# 3067M register map
File version: 1.0
Registers are 32-bit, access per field, reset 0x0 unless marked. A register's access mark holds for its fields unless they carry their own. Offsets are from the block's base; [hi:lo] are bit positions; {n}, {i} and the like mark numbered series.

## APT0 (part 1 of 2) — APT0 peripheral interface
Base 0x14A00000
Same registers: APT{n} {0x14A00000+0x1000*n} (n=1..15)
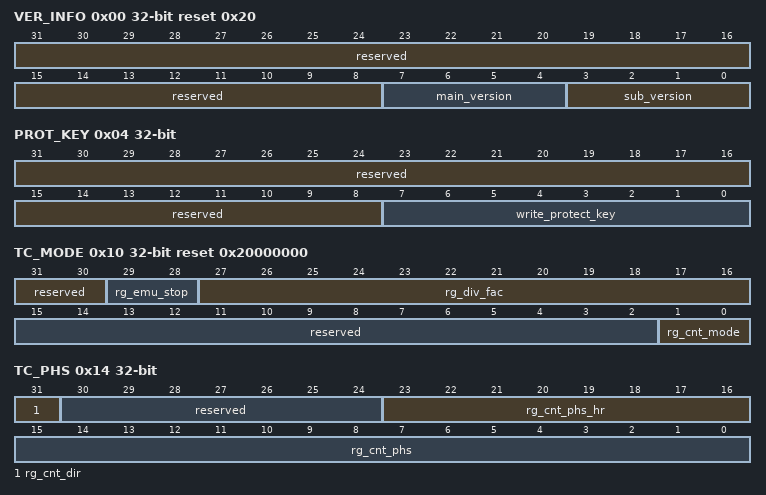
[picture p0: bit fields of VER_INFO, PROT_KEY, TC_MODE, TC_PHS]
0x00 VER_INFO ro reset 0x20 — VER_INFO为版本信息寄存器。
  [31:8] reserved — 保留。
  [7:4] main_version — 主版本号。
  [3:0] sub_version — 子版本号。
0x04 PROT_KEY — PROT_KEY为保护配置寄存器。
  [31:8] reserved ro — 保留。
  [7:0] write_protect_key rw — 写保护关键字。 0x55：软件可写支持写保护的寄存器； 其他：软件不可写支持写保护的寄存器，只可读。
0x10 TC_MODE reset 0x20000000 — TC_MODE为计数模式寄存器。
  [31:30] reserved ro — 保留。
  [29:28] rg_emu_stop rw — CPU debug模式，APT停止的方式。注意，如果停止APT，那么在CPU debug模式下，整个APT都会停止工作，包括输出控制功能。 0X：不停止； 10：停止分频计数器（DIVCNT）和时基计数器（TCCNT）； 11：停止APT。
  [27:16] rg_div_fac rw — 分频系数。 分频倍数 = 分频系数 +1。
  [15:2] reserved ro — 保留。
  [1:0] rg_cnt_mode rw — 时基计数器（TCCNT）的工作模式。 00：递增计数； 01：递减计数； 10：先增后减计数； 11：冻结。
0x14 TC_PHS — TC_PHS为计数相位控制寄存器。
  [31] rg_cnt_dir rw — 当APTCNTSYNC有效时，更新时基计数器（TCCNT）的计数方向，仅在先增后减计数模式有效。 0：递减； 1：递增。
  [30:24] reserved ro — 保留。
  [23:16] rg_cnt_phs_hr rw — 当APTCNTSYNC有效时，更新时基计数器（TCCNT）的计数值，高精度部分。
  [15:0] rg_cnt_phs rw — 当APTCNTSYNC有效时，更新时基计数器（TCCNT）的计数值。
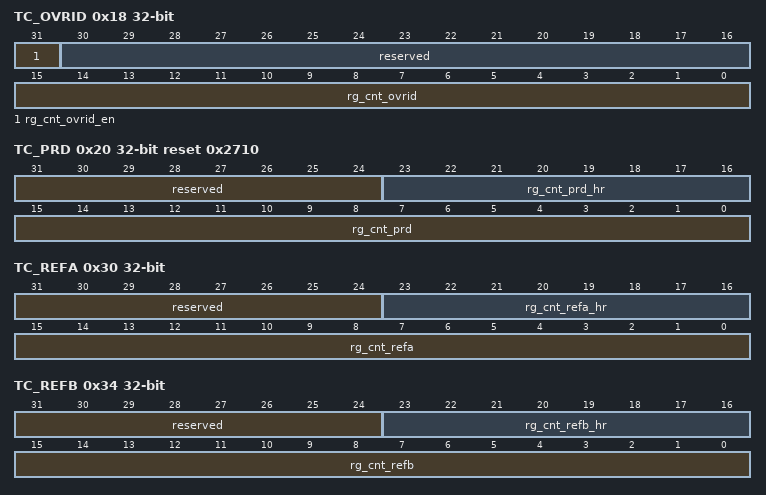
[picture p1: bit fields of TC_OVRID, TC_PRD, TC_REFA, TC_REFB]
0x18 TC_OVRID — TC_OVRID为计数器初始化寄存器。
  [31] rg_cnt_ovrid_en rw write-1-clears — 时基计数器（TCCNT）和分频计数器（DIVCNT）的初始化使能。 0：无效； 1：初始化时基计数器（TCCNT）为rg_cnt_ovrid，初始化分频计数器（DIVCNT）为0。
  [30:16] reserved ro — 保留。
  [15:0] rg_cnt_ovrid rw — 初始化时基计数器（TCCNT）的计数值。
0x20 TC_PRD reset 0x2710 — TC_PRD为计数周期寄存器。支持LINK。
  [31:24] reserved ro — 保留。
  [23:16] rg_cnt_prd_hr rw — 时基计数器（TCCNT）的计数周期，高精度部分。
  [15:0] rg_cnt_prd rw — 时基计数器（TCCNT）的计数周期。
0x30 TC_REFA — TC_REFA为计数参考值A寄存器。支持LINK。
  [31:24] reserved ro — 保留。
  [23:16] rg_cnt_refa_hr rw — 时基计数器（TCCNT）的参考值A，高精度部分。
  [15:0] rg_cnt_refa rw — 时基计数器（TCCNT）的参考值A。
0x34 TC_REFB — TC_REFB为计数参考值B寄存器。支持LINK。
  [31:24] reserved ro — 保留。
  [23:16] rg_cnt_refb_hr rw — 时基计数器（TCCNT）的参考值B，高精度部分。
  [15:0] rg_cnt_refb rw — 时基计数器（TCCNT）的参考值B。
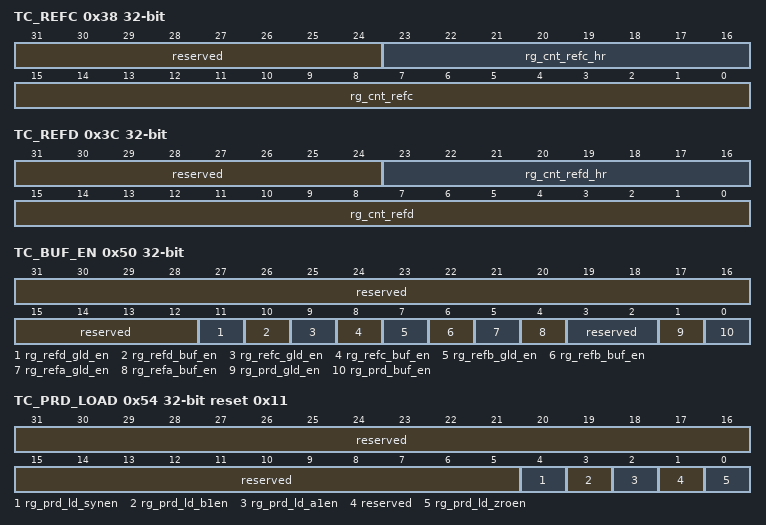
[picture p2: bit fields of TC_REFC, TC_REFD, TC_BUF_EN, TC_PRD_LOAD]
0x38 TC_REFC — TC_REFC为计数参考值C寄存器。支持LINK。
  [31:24] reserved ro — 保留。
  [23:16] rg_cnt_refc_hr rw — 时基计数器（TCCNT）的参考值C，高精度部分。
  [15:0] rg_cnt_refc rw — 时基计数器（TCCNT）的参考值C。
0x3C TC_REFD — TC_REFD为计数参考值D寄存器。支持LINK。
  [31:24] reserved ro — 保留。
  [23:16] rg_cnt_refd_hr rw — 时基计数器（TCCNT）的参考值D，高精度部分。
  [15:0] rg_cnt_refd rw — 时基计数器（TCCNT）的参考值D。
0x50 TC_BUF_EN — TC_BUF_EN为计数器缓存加载使能寄存器。
  [31:12] reserved ro — 保留。
  [11] rg_refd_gld_en rw — TC_REFD寄存器的缓存加载模式选择。 0：独立加载； 1：全局加载。
  [10] rg_refd_buf_en rw — TC_REFD寄存器的缓存使能。 0：不使能； 1：使能。
  [9] rg_refc_gld_en rw — TC_REFC寄存器的缓存加载模式选择。 0：独立加载； 1：全局加载。
  [8] rg_refc_buf_en rw — TC_REFC寄存器的缓存使能。 0：不使能； 1：使能。
  [7] rg_refb_gld_en rw — TC_REFB寄存器的缓存加载模式选择。 0：独立加载； 1：全局加载。
  [6] rg_refb_buf_en rw — TC_REFB寄存器的缓存使能。 0：不使能； 1：使能。
  [5] rg_refa_gld_en rw — TC_REFA寄存器的缓存加载模式选择。 0：独立加载； 1：全局加载。
  [4] rg_refa_buf_en rw — TC_REFA寄存器的缓存使能。 0：不使能； 1：使能。
  [3:2] reserved ro — 保留。
  [1] rg_prd_gld_en rw — TC_PRD寄存器的缓存加载模式选择。 0：独立加载； 1：全局加载。
  [0] rg_prd_buf_en rw — TC_PRD寄存器的缓存使能。 0：不使能； 1：使能。
0x54 TC_PRD_LOAD reset 0x11 — TC_PRD_LOAD为计数周期寄存器独立加载触发信号选择寄存器。
  [31:5] reserved ro — 保留。
  [4] rg_prd_ld_synen rw — 选择APTxSYNCI有效时，是否使能TC_PRD寄存器的独立加载。 0：不使能； 1：使能。
  [3] rg_prd_ld_b1en rw — 选择EMEVTB1有效时，是否使能TC_PRD寄存器的独立加载。 0：不使能； 1：使能。
  [2] rg_prd_ld_a1en rw — 选择EMEVTA1有效时，是否使能TC_PRD寄存器的独立加载。 0：不使能； 1：使能。
  [1] reserved ro — 保留。
  [0] rg_prd_ld_zroen rw — 选择CNT_ZERO有效时，是否使能TC_PRD寄存器的独立加载。 0：不使能； 1：使能。
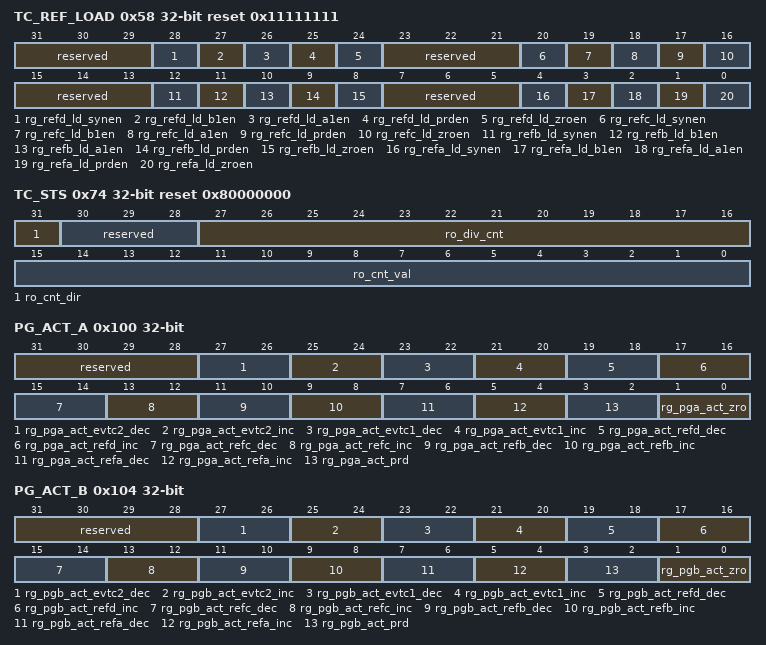
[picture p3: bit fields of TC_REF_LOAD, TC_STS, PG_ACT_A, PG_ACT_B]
0x58 TC_REF_LOAD reset 0x11111111 — TC_REF_LOAD为计数参考值寄存器独立加载触发信号选择寄存器。
  [31:29] reserved ro — 保留。
  [28] rg_refd_ld_synen rw — 选择APTxSYNCI有效时，是否使能TC_REFD寄存器的独立加载。 0：不使能； 1：使能。
  [27] rg_refd_ld_b1en rw — 选择EMEVTB1有效时，是否使能TC_REFD寄存器的独立加载。 0：不使能； 1：使能。
  [26] rg_refd_ld_a1en rw — 选择EMEVTA1有效时，是否使能TC_REFD寄存器的独立加载。 0：不使能； 1：使能。
  [25] rg_refd_ld_prden rw — 选择CNT_PRD有效时，是否使能TC_REFD寄存器的独立加载。 0：不使能； 1：使能。
  [24] rg_refd_ld_zroen rw — 选择CNT_ZERO有效时，是否使能TC_REFD寄存器的独立加载。 0：不使能； 1：使能。
  [23:21] reserved ro — 保留。
  [20] rg_refc_ld_synen rw — 选择APTxSYNCI有效时，是否使能TC_REFC寄存器的独立加载。 0：不使能； 1：使能。
  [19] rg_refc_ld_b1en rw — 选择EMEVTB1有效时，是否使能TC_REFC寄存器的独立加载。 0：不使能； 1：使能。
  [18] rg_refc_ld_a1en rw — 选择EMEVTA1有效时，是否使能TC_REFC寄存器的独立加载。 0：不使能； 1：使能。
  [17] rg_refc_ld_prden rw — 选择CNT_PRD有效时，是否使能TC_REFC寄存器的独立加载。 0：不使能； 1：使能。
  [16] rg_refc_ld_zroen rw — 选择CNT_ZERO有效时，是否使能TC_REFC寄存器的独立加载。 0：不使能； 1：使能。
  [15:13] reserved ro — 保留。
  [12] rg_refb_ld_synen rw — 选择APTxSYNCI有效时，是否使能TC_REFB寄存器的独立加载。 0：不使能； 1：使能。
  [11] rg_refb_ld_b1en rw — 选择EMEVTB1有效时，是否使能TC_REFB寄存器的独立加载。 0：不使能； 1：使能。
  [10] rg_refb_ld_a1en rw — 选择EMEVTA1有效时，是否使能TC_REFB寄存器的独立加载。 0：不使能； 1：使能。
  [9] rg_refb_ld_prden rw — 选择CNT_PRD有效时，是否使能TC_REFB寄存器的独立加载。 0：不使能； 1：使能。
  [8] rg_refb_ld_zroen rw — 选择CNT_ZERO有效时，是否使能TC_REFB寄存器的独立加载。 0：不使能； 1：使能。
  [7:5] reserved ro — 保留。
  [4] rg_refa_ld_synen rw — 选择APTxSYNCI有效时，是否使能TC_REFA寄存器的独立加载。 0：不使能； 1：使能。
  [3] rg_refa_ld_b1en rw — 选择EMEVTB1有效时，是否使能TC_REFA寄存器的独立加载。 0：不使能； 1：使能。
  [2] rg_refa_ld_a1en rw — 选择EMEVTA1有效时，是否使能TC_REFA寄存器的独立加载。 0：不使能； 1：使能。
  [1] rg_refa_ld_prden rw — 选择CNT_PRD有效时，是否使能TC_REFA寄存器的独立加载。 0：不使能； 1：使能。
  [0] rg_refa_ld_zroen rw — 选择CNT_ZERO有效时，是否使能TC_REFA寄存器的独立加载。 0：不使能； 1：使能。
0x74 TC_STS ro reset 0x80000000 — TC_STS为计数状态寄存器。
  [31] ro_cnt_dir — 时基计数器（TCCNT）的当前计数方向。 0：递减计数； 1：递增计数。
  [30:28] reserved — 保留。
  [27:16] ro_div_cnt — 分频计数器（DIVCNT）的当前计数值。
  [15:0] ro_cnt_val — 时基计数器（TCCNT）的当前计数值。
0x100 PG_ACT_A — PG_ACT_A为PG_PWMA动作配置寄存器。支持LINK。
  [31:28] reserved ro — 保留。
  [27:26] rg_pga_act_evtc2_dec rw — AEVTC2有效且TCCNT计数方向递减时，PG_PWMA的动作。 00：无影响； 01：置为低电平； 10：置为高电平； 11：翻转电平。
  [25:24] rg_pga_act_evtc2_inc rw — AEVTC2有效且TCCNT计数方向递增时，PG_PWMA的动作。 00：无影响； 01：置为低电平； 10：置为高电平； 11：翻转电平。
  [23:22] rg_pga_act_evtc1_dec rw — AEVTC1有效且TCCNT计数方向递减时，PG_PWMA的动作。 00：无影响； 01：置为低电平； 10：置为高电平； 11：翻转电平。
  [21:20] rg_pga_act_evtc1_inc rw — AEVTC1有效且TCCNT计数方向递增时，PG_PWMA的动作。 00：无影响； 01：置为低电平； 10：置为高电平； 11：翻转电平。
  [19:18] rg_pga_act_refd_dec rw — CNT_REFD有效且TCCNT计数方向递减时，PG_PWMA的动作。 00：无影响； 01：置为低电平； 10：置为高电平； 11：翻转电平。
  [17:16] rg_pga_act_refd_inc rw — CNT_REFD有效且TCCNT计数方向递增时，PG_PWMA的动作。 00：无影响； 01：置为低电平； 10：置为高电平； 11：翻转电平。
  [15:14] rg_pga_act_refc_dec rw — CNT_REFC有效且TCCNT计数方向递减时，PG_PWMA的动作。 00：无影响； 01：置为低电平； 10：置为高电平； 11：翻转电平。
  [13:12] rg_pga_act_refc_inc rw — CNT_REFC有效且TCCNT计数方向递增时，PG_PWMA的动作。 00：无影响； 01：置为低电平； 10：置为高电平； 11：翻转电平。
  [11:10] rg_pga_act_refb_dec rw — CNT_REFB有效且TCCNT计数方向递减时，PG_PWMA的动作。 00：无影响； 01：置为低电平； 10：置为高电平； 11：翻转电平。
  [9:8] rg_pga_act_refb_inc rw — CNT_REFB有效且TCCNT计数方向递增时，PG_PWMA的动作。 00：无影响； 01：置为低电平； 10：置为高电平； 11：翻转电平。
  [7:6] rg_pga_act_refa_dec rw — CNT_REFA有效且TCCNT计数方向递减时，PG_PWMA的动作。 00：无影响； 01：置为低电平； 10：置为高电平； 11：翻转电平。
  [5:4] rg_pga_act_refa_inc rw — CNT_REFA有效且TCCNT计数方向递增时，PG_PWMA的动作。 00：无影响； 01：置为低电平； 10：置为高电平； 11：翻转电平。
  [3:2] rg_pga_act_prd rw — CNT_PRD有效时，PG_PWMA的动作。 00：无影响； 01：置为低电平； 10：置为高电平； 11：翻转电平。
  [1:0] rg_pga_act_zro rw — CNT_ZERO有效时，PG_PWMA的动作。 00：无影响； 01：置为低电平； 10：置为高电平； 11：翻转电平。
0x104 PG_ACT_B — PG_ACT_B为PG_PWMB动作配置寄存器。支持LINK。
  [31:28] reserved ro — 保留。
  [27:26] rg_pgb_act_evtc2_dec rw — BEVTC2有效且TCCNT计数方向递减时，PG_PWMB的动作。 00：无影响； 01：置为低电平； 10：置为高电平； 11：翻转电平。
  [25:24] rg_pgb_act_evtc2_inc rw — BEVTC2有效且TCCNT计数方向递增时，PG_PWMB的动作。 00：无影响； 01：置为低电平； 10：置为高电平； 11：翻转电平。
  [23:22] rg_pgb_act_evtc1_dec rw — BEVTC1有效且TCCNT计数方向递减时，PG_PWMB的动作。 00：无影响； 01：置为低电平； 10：置为高电平； 11：翻转电平。
  [21:20] rg_pgb_act_evtc1_inc rw — BEVTC1有效且TCCNT计数方向递增时，PG_PWMB的动作。 00：无影响； 01：置为低电平； 10：置为高电平； 11：翻转电平。
  [19:18] rg_pgb_act_refd_dec rw — CNT_REFD有效且TCCNT计数方向递减时，PG_PWMB的动作。 00：无影响； 01：置为低电平； 10：置为高电平； 11：翻转电平。
  [17:16] rg_pgb_act_refd_inc rw — CNT_REFD有效且TCCNT计数方向递增时，PG_PWMB的动作。 00：无影响； 01：置为低电平； 10：置为高电平； 11：翻转电平。
  [15:14] rg_pgb_act_refc_dec rw — CNT_REFC有效且TCCNT计数方向递减时，PG_PWMB的动作。 00：无影响； 01：置为低电平； 10：置为高电平； 11：翻转电平。
  [13:12] rg_pgb_act_refc_inc rw — CNT_REFC有效且TCCNT计数方向递增时，PG_PWMB的动作。 00：无影响； 01：置为低电平； 10：置为高电平； 11：翻转电平。
  [11:10] rg_pgb_act_refb_dec rw — CNT_REFB有效且TCCNT计数方向递减时，PG_PWMB的动作。 00：无影响； 01：置为低电平； 10：置为高电平； 11：翻转电平。
  [9:8] rg_pgb_act_refb_inc rw — CNT_REFB有效且TCCNT计数方向递增时，PG_PWMB的动作。 00：无影响； 01：置为低电平； 10：置为高电平； 11：翻转电平。
  [7:6] rg_pgb_act_refa_dec rw — CNT_REFA有效且TCCNT计数方向递减时，PG_PWMB的动作。 00：无影响； 01：置为低电平； 10：置为高电平； 11：翻转电平。
  [5:4] rg_pgb_act_refa_inc rw — CNT_REFA有效且TCCNT计数方向递增时，PG_PWMB的动作。 00：无影响； 01：置为低电平； 10：置为高电平； 11：翻转电平。
  [3:2] rg_pgb_act_prd rw — CNT_PRD有效时，PG_PWMB的动作。 00：无影响； 01：置为低电平； 10：置为高电平； 11：翻转电平。
  [1:0] rg_pgb_act_zro rw — CNT_ZERO有效时，PG_PWMB的动作。 00：无影响； 01：置为低电平； 10：置为高电平； 11：翻转电平。
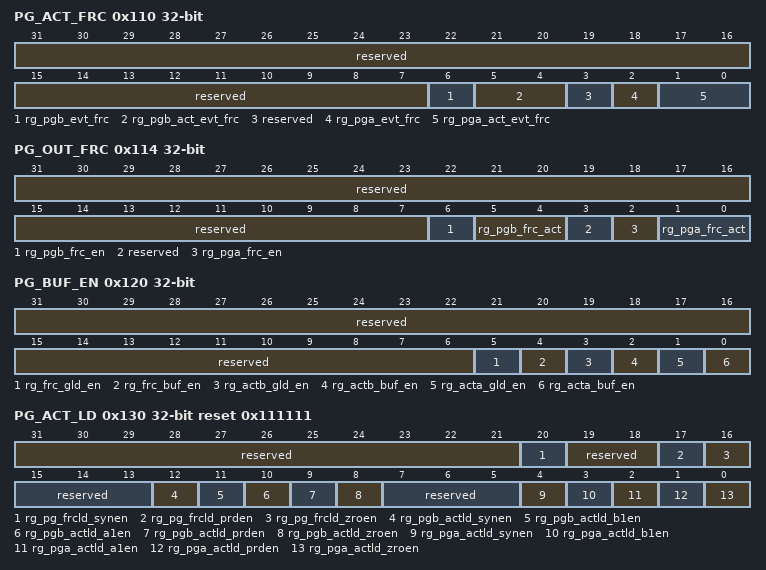
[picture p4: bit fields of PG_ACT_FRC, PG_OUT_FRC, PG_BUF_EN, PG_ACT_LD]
0x110 PG_ACT_FRC — PG_ACT_FRC为强制动作配置寄存器。支持LINK。
  [31:7] reserved ro — 保留。
  [6] rg_pgb_evt_frc rw write-1-clears — 软件强制PG_PWMB动作，每次写1产生一次PG_PWMB动作，然后自动清零。 0：写0无效； 1：写1有效。
  [5:4] rg_pgb_act_evt_frc rw — 软件强制PG_PWMB动作有效时，PG_PWMB的动作。 00：无影响； 01：置为低电平； 10：置为高电平； 11：翻转电平。
  [3] reserved ro — 保留。
  [2] rg_pga_evt_frc rw write-1-clears — 软件强制PG_PWMA动作，每次写1产生一次PG_PWMA动作，然后自动清零。 0：写0无效； 1：写1有效。
  [1:0] rg_pga_act_evt_frc rw — 软件强制PG_PWMA动作有效时，PG_PWMA的动作。 00：无影响； 01：置为低电平； 10：置为高电平； 11：翻转电平。
0x114 PG_OUT_FRC — PG_OUT_FRC为强制输出配置寄存器。支持LINK。
  [31:7] reserved ro — 保留。
  [6] rg_pgb_frc_en rw — PG_PWMB软件强制输出使能。 0：不使能； 1：使能。
  [5:4] rg_pgb_frc_act rw — PG_PWMB软件强制输出使能时，PG_PWMB的输出状态。 00：锁定电平； 01：置为低电平； 10：置为高电平； 11：保留。
  [3] reserved ro — 保留。
  [2] rg_pga_frc_en rw — PG_PWMA软件强制输出使能。 0：不使能； 1：使能。
  [1:0] rg_pga_frc_act rw — PG_PWMA软件强制输出使能时，PG_PWMA的输出状态。 00：锁定电平； 01：置为低电平； 10：置为高电平； 11：保留。
0x120 PG_BUF_EN — PG_BUF_EN为波形生成缓存使能寄存器。
  [31:6] reserved ro — 保留。
  [5] rg_frc_gld_en rw — PG_OUT_FRC寄存器的缓存加载模式选择。 0：独立加载； 1：全局加载。
  [4] rg_frc_buf_en rw — PG_OUT_FRC寄存器的缓存使能。 0：不使能； 1：使能。
  [3] rg_actb_gld_en rw — PG_ACT_B寄存器的缓存加载模式选择。 0：独立加载； 1：全局加载。
  [2] rg_actb_buf_en rw — PG_ACT_B寄存器的缓存使能。 0：不使能； 1：使能。
  [1] rg_acta_gld_en rw — PG_ACT_A寄存器的缓存加载模式选择。 0：独立加载； 1：全局加载。
  [0] rg_acta_buf_en rw — PG_ACT_A寄存器的缓存使能。 0：不使能； 1：使能。
0x130 PG_ACT_LD reset 0x111111 — PG_ACT_LD为波形生成动作独立加载触发信号选择寄存器。
  [31:21] reserved ro — 保留。
  [20] rg_pg_frcld_synen rw — 选择APTxSYNCI有效时，是否使能PG_OUT_FRC寄存器的独立加载。 0：不使能； 1：使能。
  [19:18] reserved ro — 保留。
  [17] rg_pg_frcld_prden rw — 选择CNT_PRD有效时，是否使能PG_OUT_FRC寄存器的独立加载。 0：不使能； 1：使能。
  [16] rg_pg_frcld_zroen rw — 选择CNT_ZERO有效时，是否使能PG_OUT_FRC寄存器的独立加载。 0：不使能； 1：使能。
  [15:13] reserved ro — 保留。
  [12] rg_pgb_actld_synen rw — 选择APTxSYNCI有效时，是否使能PG_ACT_B寄存器的独立加载。 0：不使能； 1：使能。
  [11] rg_pgb_actld_b1en rw — 选择EMEVTB1有效时，是否使能PG_ACT_B寄存器的独立加载。 0：不使能； 1：使能。
  [10] rg_pgb_actld_a1en rw — 选择EMEVTA1有效时，是否使能PG_ACT_B寄存器的独立加载。 0：不使能； 1：使能。
  [9] rg_pgb_actld_prden rw — 选择CNT_PRD有效时，是否使能PG_ACT_B寄存器的独立加载。 0：不使能； 1：使能。
  [8] rg_pgb_actld_zroen rw — 选择CNT_ZERO有效时，是否使能PG_ACT_B寄存器的独立加载。 0：不使能； 1：使能。
  [7:5] reserved ro — 保留。
  [4] rg_pga_actld_synen rw — 选择APTxSYNCI有效时，是否使能PG_ACT_A寄存器的独立加载。 0：不使能； 1：使能。
  [3] rg_pga_actld_b1en rw — 选择EMEVTB1有效时，是否使能PG_ACT_A寄存器的独立加载。 0：不使能； 1：使能。
  [2] rg_pga_actld_a1en rw — 选择EMEVTA1有效时，是否使能PG_ACT_A寄存器的独立加载。 0：不使能； 1：使能。
  [1] rg_pga_actld_prden rw — 选择CNT_PRD有效时，是否使能PG_ACT_A寄存器的独立加载。 0：不使能； 1：使能。
  [0] rg_pga_actld_zroen rw — 选择CNT_ZERO有效时，是否使能PG_ACT_A寄存器的独立加载。 0：不使能； 1：使能。
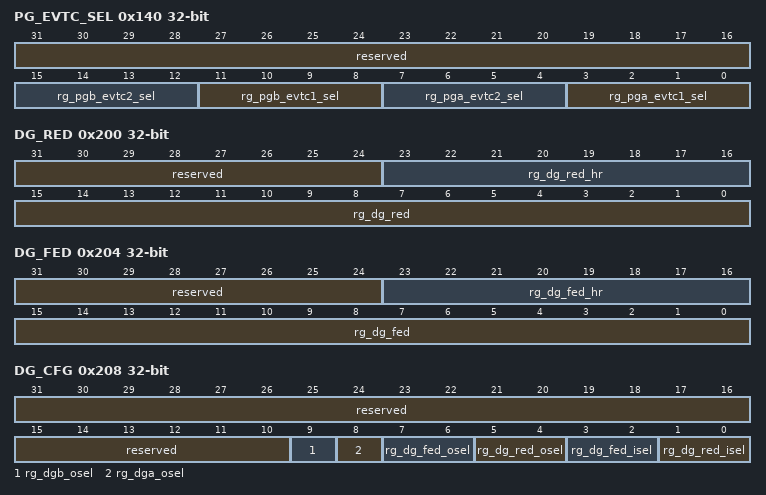
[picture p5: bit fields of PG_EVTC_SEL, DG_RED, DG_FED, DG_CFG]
0x140 PG_EVTC_SEL — PG_EVTC_SEL为波形生成事件C触发源选择寄存器。
  [31:16] reserved ro — 保留。
  [15:12] rg_pgb_evtc2_sel rw — BEVTC2触发源选择。 0x1：EMEVTA1_TEMP； 0x2：EMEVTA2_TEMP； 0x3：EMEVTB1_TEMP； 0x4：EMEVTB2_TEMP； 0x5：EMEVTFILT； 0x6：TRIP1； 0x7：TRIP2； 0x8：TRIP3； 0x9：APTxSYNCI； 其他：禁止产生BEVTC2。
  [11:8] rg_pgb_evtc1_sel rw — BEVTC1触发源选择。 0x1：EMEVTA1_TEMP； 0x2：EMEVTA2_TEMP； 0x3：EMEVTB1_TEMP； 0x4：EMEVTB2_TEMP； 0x5：EMEVTFILT； 0x6：TRIP1； 0x7：TRIP2； 0x8：TRIP3； 0x9：APTxSYNCI； 其他：禁止产生BEVTC1。
  [7:4] rg_pga_evtc2_sel rw — AEVTC2触发源选择。 0x1：EMEVTA1_TEMP； 0x2：EMEVTA2_TEMP； 0x3：EMEVTB1_TEMP； 0x4：EMEVTB2_TEMP； 0x5：EMEVTFILT； 0x6：TRIP1； 0x7：TRIP2； 0x8：TRIP3； 0x9：APTxSYNCI； 其他：禁止产生AEVTC2。
  [3:0] rg_pga_evtc1_sel rw — AEVTC1触发源选择。 0x1：EMEVTA1_TEMP； 0x2：EMEVTA2_TEMP； 0x3：EMEVTB1_TEMP； 0x4：EMEVTB2_TEMP； 0x5：EMEVTFILT； 0x6：TRIP1； 0x7：TRIP2； 0x8：TRIP3； 0x9：APTxSYNCI； 其他：禁止产生AEVTC1。
0x200 DG_RED — DG_RED为死区上升沿延时配置寄存器。支持LINK。
  [31:24] reserved ro — 保留。
  [23:16] rg_dg_red_hr rw — 死区上升沿延时配置，高精度部分。
  [15:0] rg_dg_red rw — 死区上升沿延时配置。
0x204 DG_FED — DG_FED为死区下降沿延时配置寄存器。支持LINK。
  [31:24] reserved ro — 保留。
  [23:16] rg_dg_fed_hr rw — 死区下降沿延时配置，高精度部分。
  [15:0] rg_dg_fed rw — 死区下降沿延时配置。
0x208 DG_CFG — DG_CFG为死区配置寄存器。支持LINK。
  [31:10] reserved ro — 保留。
  [9] rg_dgb_osel rw — 选择DG_PWMB的源。 0：选择PWM_FED_POL作为DG_PWMB； 1：选择PWM_RED_POL作为DG_PWMB。
  [8] rg_dga_osel rw — 选择DG_PWMA的源。 0：选择PWM_RED_POL作为DG_PWMA； 1：选择PWM_FED_POL作为DG_PWMA。
  [7:6] rg_dg_fed_osel rw — 选择PWM_FED_POL的源。 0X：选择PWM_FED_AFTER作为PWM_FED_POL； 10：选择PWM_FED_AFTER取反后作为PWM_FED_POL； 11：选择PG_PWMB作为PWM_FED_POL。
  [5:4] rg_dg_red_osel rw — 选择PWM_RED_POL的源。 0X：选择PWM_RED_AFTER作为PWM_RED_POL； 10：选择PWM_RED_AFTER取反后作为PWM_RED_POL； 11：选择PG_PWMA作为PWM_RED_POL。
  [3:2] rg_dg_fed_isel rw — 选择PWM_FED_BEFORE的源。 00：选择PG_PWMB作为PWM_FED_BEFORE； 01：选择PG_PWMA作为PWM_FED_BEFORE； 10：选择PWM_RED_AFTER作为PWM_FED_BEFORE； 11：将PWM_FED_BEFORE固定为低电平。
  [1:0] rg_dg_red_isel rw — 选择PWM_RED_BEFORE的源。 X0：选择PG_PWMA作为PWM_RED_BEFORE； X1：选择PG_PWMB作为PWM_RED_BEFORE。
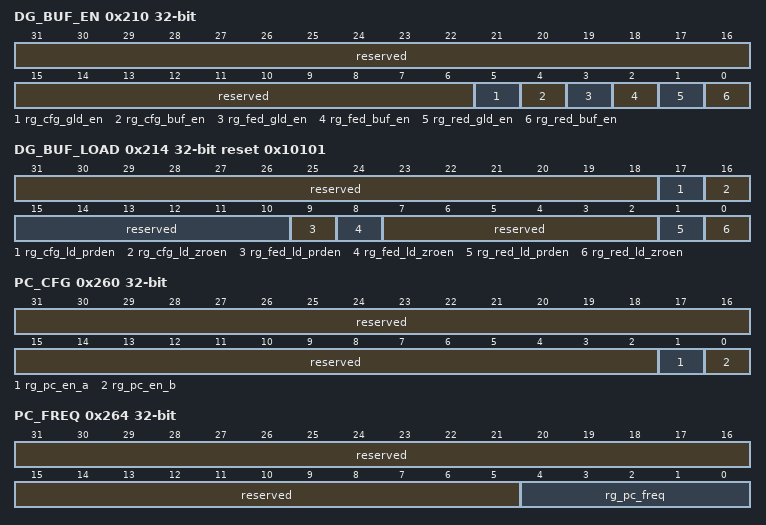
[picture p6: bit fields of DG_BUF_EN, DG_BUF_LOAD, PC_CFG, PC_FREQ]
0x210 DG_BUF_EN — DG_BUF_EN为死区生成缓存使能寄存器。
  [31:6] reserved ro — 保留。
  [5] rg_cfg_gld_en rw — DG_CFG寄存器的缓存加载模式选择。 0：独立加载； 1：全局加载。
  [4] rg_cfg_buf_en rw — DG_CFG寄存器的缓存使能。 0：不使能； 1：使能。
  [3] rg_fed_gld_en rw — DG_FED寄存器的缓存加载模式选择。 0：独立加载； 1：全局加载。
  [2] rg_fed_buf_en rw — DG_FED寄存器的缓存使能。 0：不使能； 1：使能。
  [1] rg_red_gld_en rw — DG_RED寄存器的缓存加载模式选择。 0：独立加载； 1：全局加载。
  [0] rg_red_buf_en rw — DG_RED寄存器的缓存使能。 0：不使能； 1：使能。
0x214 DG_BUF_LOAD reset 0x10101 — DG_BUF_LOAD为死区生成独立加载触发信号选择寄存器。
  [31:18] reserved ro — 保留。
  [17] rg_cfg_ld_prden rw — 选择CNT_PRD有效时，是否使能DG_CFG寄存器的独立加载。 0：不使能； 1：使能。
  [16] rg_cfg_ld_zroen rw — 选择CNT_ZERO有效时，是否使能DG_CFG寄存器的独立加载。 0：不使能； 1：使能。
  [15:10] reserved ro — 保留。
  [9] rg_fed_ld_prden rw — 选择CNT_PRD有效时，是否使能DG_FED寄存器的独立加载。 0：不使能； 1：使能。
  [8] rg_fed_ld_zroen rw — 选择CNT_ZERO有效时，是否使能DG_FED寄存器的独立加载。 0：不使能； 1：使能。
  [7:2] reserved ro — 保留。
  [1] rg_red_ld_prden rw — 选择CNT_PRD有效时，是否使能DG_RED寄存器的独立加载。 0：不使能； 1：使能。
  [0] rg_red_ld_zroen rw — 选择CNT_ZERO有效时，是否使能DG_RED寄存器的独立加载。 0：不使能； 1：使能。
0x260 PC_CFG — PC_CFG为PC (PWM Chopper)斩波配置寄存器。支持LINK。
  [31:2] reserved ro — 保留。
  [1] rg_pc_en_a rw — B路斩波使能。 0：不使能，旁路斩波功能； 1：使能。
  [0] rg_pc_en_b rw — A路斩波使能。 0：不使能，旁路斩波功能； 1：使能。
0x264 PC_FREQ — PC_FREQ为斩波时钟频率配置寄存器。
  [31:5] reserved ro — 保留。
  [4:0] rg_pc_freq rw — 斩波时钟PSCLK频率配置。 0x0：8分频，斩波时钟PSCLK频率=APTCLK频率/8； 0x1：16分频，斩波时钟PSCLK频率=APTCLK频率/16； 0x2：24分频，斩波时钟PSCLK频率=APTCLK频率/24； 0x3：32分频，斩波时钟PSCLK频率=APTCLK频率/32； … 0x1F：256分频，斩波时钟PSCLK频率=APTCLK频率/256。
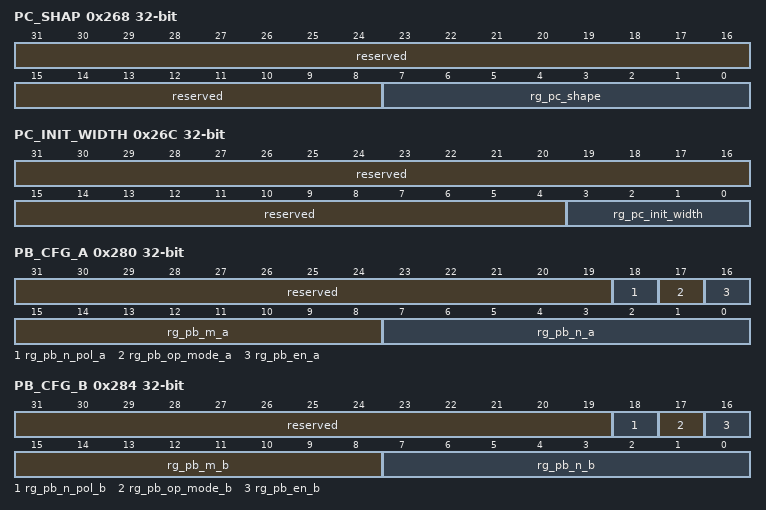
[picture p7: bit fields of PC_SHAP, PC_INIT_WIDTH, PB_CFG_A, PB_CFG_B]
0x268 PC_SHAP — PC_SHAP为斩波时钟形状配置寄存器。
  [31:8] reserved ro — 保留。
  [7:0] rg_pc_shape rw — 斩波时钟PSCLK形状配置。 PSCLK分为8份，8bit配置分别对应8份。 0x0：二进制00000000，8份均为0，占空比为0，斩波输出只有初始脉冲； 0x1：二进制00000001，8份中前7份为0，最后1份为1，斩波时钟PSCLK占空比为1/8，12.5%； 0x2：二进制00000010，8份中前6份和最后1份为0，第7份为1，斩波时钟PSCLK占空比为1/8，12.5%； 0x3：二进制00000011，8份中前6份为0，最后2份为1，斩波时钟PSCLK占空比为2/8，25%； … 0x7F：二进制01111111，8份中第1份为0，剩下7份均为1，斩波时钟PSCLK占空比为7/8，87.5%。
0x26C PC_INIT_WIDTH — PC_INIT_WIDTH为斩波初始脉冲宽度配置寄存器。
  [31:4] reserved ro — 保留。
  [3:0] rg_pc_init_width rw — 斩波初始脉冲宽度。 0x0：1个PSCLK周期时间； 0x1：2个PSCLK周期时间； 0x2：3个PSCLK周期时间； … 0xF：16个PSCLK周期时间。
0x280 PB_CFG_A — PB_CFG_A为PB_PWMA配置寄存器。支持LINK。
  [31:19] reserved ro — 保留。
  [18] rg_pb_n_pol_a rw — PWMA Burst封波电平。 0：Burst封波输出低电平； 1：Burst封波输出高电平。
  [17] rg_pb_op_mode_a rw — PWMA Burst工作模式。 0：先限制N个周期PWM波输出为0； 1：先正常输出M-N个周期PWM波。
  [16] rg_pb_en_a rw — PWMA Burst使能。 0：不使能，旁路PB； 1：使能。
  [15:8] rg_pb_m_a rw — PWMA Burst周期M，单次Burst持续M个PWM周期。 注意：rg_pb_m配置须大于等于rg_pb_n。
  [7:0] rg_pb_n_a rw — PWMA Burst封波周期N。在M个PWM周期中，N个周期限制PWM波输出为0，剩下M-N个周期PWM波正常输出。
0x284 PB_CFG_B — PB_CFG_B为PB_PWMB配置寄存器。支持LINK。
  [31:19] reserved ro — 保留。
  [18] rg_pb_n_pol_b rw — PWMB Burst封波电平。 0：Burst封波输出低电平； 1：Burst封波输出高电平。
  [17] rg_pb_op_mode_b rw — PWMB Burst工作模式。 0：先限制N个周期PWM波输出为0； 1：先正常输出M-N个周期PWM波。
  [16] rg_pb_en_b rw — PWMB Burst使能。 0：不使能，旁路PB； 1：使能。
  [15:8] rg_pb_m_b rw — PWMB Burst周期M，单次Burst持续M个PWM周期。 注意：rg_pb_m配置须大于等于rg_pb_n。
  [7:0] rg_pb_n_b rw — PWMB 封波周期N。在M个PWM周期中，N个周期限制PWM波输出为0，剩下M-N个周期PWM波正常输出。
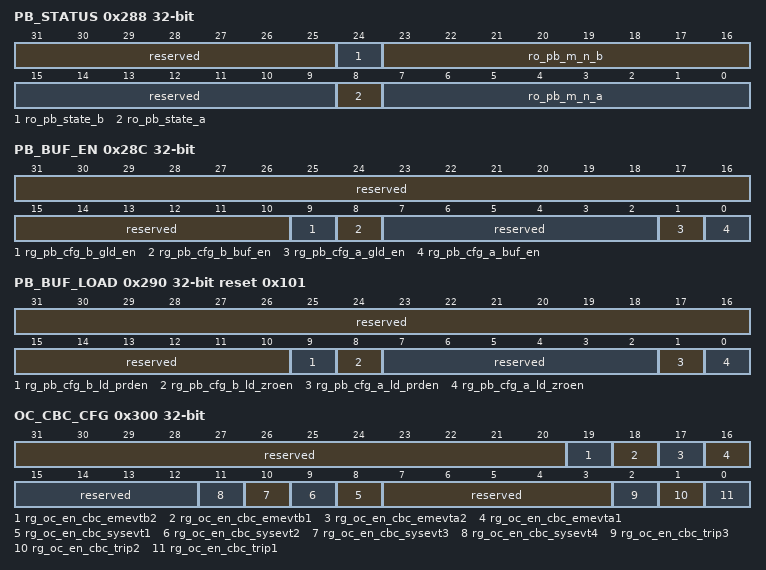
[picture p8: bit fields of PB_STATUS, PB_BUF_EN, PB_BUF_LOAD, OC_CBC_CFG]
0x288 PB_STATUS ro — PB_STATUS为PB状态寄存器。
  [31:25] reserved — 保留。
  [24] ro_pb_state_b — PWMB Burst工作状态。 0：PWM波正常输出； 1：限制PWM波输出为0。
  [23:16] ro_pb_m_n_b — PWMB Burst工作时，当前PWM波周期数。
  [15:9] reserved — 保留。
  [8] ro_pb_state_a — PWMA Burst工作状态。 0：PWM波正常输出； 1：限制PWM波输出为0。
  [7:0] ro_pb_m_n_a — PWMA Burst工作时，当前PWM波周期数。
0x28C PB_BUF_EN — PB_BUF_EN为PB缓存使能寄存器。
  [31:10] reserved ro — 保留。
  [9] rg_pb_cfg_b_gld_en rw — PB_CFG_B寄存器的缓存加载模式选择。 0：独立加载； 1：全局加载。
  [8] rg_pb_cfg_b_buf_en rw — PB_CFG_B寄存器的缓存使能。 0：不使能； 1：使能。
  [7:2] reserved ro — 保留。
  [1] rg_pb_cfg_a_gld_en rw — PB_CFG_A寄存器的 缓存加载模式选择。 0：独立加载； 1：全局加载。
  [0] rg_pb_cfg_a_buf_en rw — PB_CFG_A寄存器的缓存使能。 0：不使能； 1：使能。
0x290 PB_BUF_LOAD reset 0x101 — PB_BUF_LOAD为PB独立加载触发信号选择寄存器。
  [31:10] reserved ro — 保留。
  [9] rg_pb_cfg_b_ld_prden rw — 选择CNT_PRD有效时，是否使能PB_CFG_B寄存器的独立加载。 0：不使能； 1：使能。
  [8] rg_pb_cfg_b_ld_zroen rw — 选择CNT_ZERO有效时，是否使能PB_CFG_B寄存器的独立加载。 0：不使能； 1：使能。
  [7:2] reserved ro — 保留。
  [1] rg_pb_cfg_a_ld_prden rw — 选择CNT_PRD有效时，是否使能PB_CFG_A寄存器的独立加载。 0：不使能； 1：使能。
  [0] rg_pb_cfg_a_ld_zroen rw — 选择CNT_ZERO有效时，是否使能PB_CFG_A寄存器的独立加载。 0：不使能； 1：使能。
0x300 OC_CBC_CFG — OC_CBC_CFG为Cycle-by-Cycle (CBC)周期性保护配置寄存器。支持写保护。
  [31:20] reserved ro — 保留。
  [19] rg_oc_en_cbc_emevtb2 rw — EMEVTB2的CBC保护使能。 0：不使能； 1：使能。
  [18] rg_oc_en_cbc_emevtb1 rw — EMEVTB1的CBC保护使能。 0：不使能； 1：使能。
  [17] rg_oc_en_cbc_emevta2 rw — EMEVTA2的CBC保护使能。 0：不使能； 1：使能。
  [16] rg_oc_en_cbc_emevta1 rw — EMEVTA1的CBC保护使能。 0：不使能； 1：使能。
  [15:12] reserved ro — 保留。
  [n+7] rg_oc_en_cbc_sysevt{n} rw (n=1..4) — SYSEVT{n} CBC保护使能。 0：不使能； 1：使能。
  [7:3] reserved ro — 保留。
  [2] rg_oc_en_cbc_trip3 rw — TRIP3 CBC保护使能。 0：不使能； 1：使能。
  [1] rg_oc_en_cbc_trip2 rw — TRIP2 CBC保护使能。 0：不使能； 1：使能。
  [0] rg_oc_en_cbc_trip1 rw — TRIP1 CBC保护使能。 0：不使能； 1：使能。
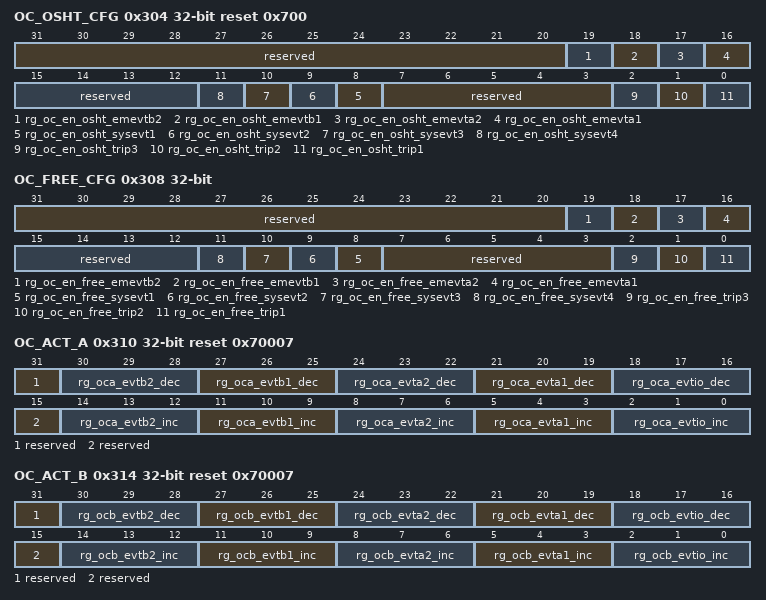
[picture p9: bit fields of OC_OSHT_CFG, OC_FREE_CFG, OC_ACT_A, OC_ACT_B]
0x304 OC_OSHT_CFG reset 0x700 — OC_OSHT_CFG为One-Shot (OSHT)持续性输出保护配置寄存器。支持写保护。
  [31:20] reserved ro — 保留。
  [19] rg_oc_en_osht_emevtb2 rw — EMEVTB2的OSHT保护使能。 0：不使能； 1：使能。
  [18] rg_oc_en_osht_emevtb1 rw — EMEVTB1的OSHT保护使能。 0：不使能； 1：使能。
  [17] rg_oc_en_osht_emevta2 rw — EMEVTA2的OSHT保护使能。 0：不使能； 1：使能。
  [16] rg_oc_en_osht_emevta1 rw — EMEVTA1的OSHT保护使能。 0：不使能； 1：使能。
  [15:12] reserved ro — 保留。
  [n+7] rg_oc_en_osht_sysevt{n} rw (n=1..4) — SYSEVT{n} OSHT保护使能。 0：不使能； 1：使能。
  [7:3] reserved ro — 保留。
  [2] rg_oc_en_osht_trip3 rw — TRIP3 OSHT保护使能。 0：不使能； 1：使能。
  [1] rg_oc_en_osht_trip2 rw — TRIP2 OSHT保护使能。 0：不使能； 1：使能。
  [0] rg_oc_en_osht_trip1 rw — TRIP1 OSHT保护使能。 0：不使能； 1：使能。
0x308 OC_FREE_CFG — OC_FREE_CFG为FREE自由输出保护配置寄存器。支持写保护。
  [31:20] reserved ro — 保留。
  [19] rg_oc_en_free_emevtb2 rw — EMEVTB2的FREE保护使能。 0：不使能； 1：使能。
  [18] rg_oc_en_free_emevtb1 rw — EMEVTB1的FREE保护使能。 0：不使能； 1：使能。
  [17] rg_oc_en_free_emevta2 rw — EMEVTA2的FREE保护使能。 0：不使能； 1：使能。
  [16] rg_oc_en_free_emevta1 rw — EMEVTA1的FREE保护使能。 0：不使能； 1：使能。
  [15:12] reserved ro — 保留。
  [n+7] rg_oc_en_free_sysevt{n} rw (n=1..4) — SYSEVT{n} FREE保护使能。 0：不使能； 1：使能。
  [7:3] reserved ro — 保留。
  [2] rg_oc_en_free_trip3 rw — TRIP3 FREE保护使能。 0：不使能； 1：使能。
  [1] rg_oc_en_free_trip2 rw — TRIP2 FREE保护使能。 0：不使能； 1：使能。
  [0] rg_oc_en_free_trip1 rw — TRIP1 FREE保护使能。 0：不使能； 1：使能。
0x310 OC_ACT_A reset 0x70007 — OC_ACT_A为APTx_PWMA输出保护寄存器。支持写保护。
  [31] reserved ro — 保留。
  [30:28] rg_oca_evtb2_dec rw — EMEVTB2有效且TCCNT计数方向递减时，APTx_PWMA的输出状态。 000：不做任何动作； 001：低电平； 010：高电平； 011：锁定电平； 100：翻转电平； 其他：高阻态。
  [27:25] rg_oca_evtb1_dec rw — EMEVTB1有效且TCCNT计数方向递减时，APTx_PWMA的输出状态。 000：不做任何动作； 001：低电平； 010：高电平； 011：锁定电平； 100：翻转电平； 其他：高阻态。
  [24:22] rg_oca_evta2_dec rw — EMEVTA2有效且TCCNT计数方向递减时，APTx_PWMA的输出状态。 000：不做任何动作； 001：低电平； 010：高电平； 011：锁定电平； 100：翻转电平； 其他：高阻态。
  [21:19] rg_oca_evta1_dec rw — EMEVTA1有效且TCCNT计数方向递减时，APTx_PWMA的输出状态。 000：不做任何动作； 001：低电平； 010：高电平； 011：锁定电平； 100：翻转电平； 其他：高阻态。
  [18:16] rg_oca_evtio_dec rw — CBC，OSHT，FREE保护生效且TCCNT计数方向递减时，APTx_PWMA的输出状态。 000：不做任何动作； 001：低电平； 010：高电平； 011：锁定电平； 100：翻转电平； 其他：高阻态。 配置OC_CBC_CFG、OC_OSHT_CFG、OC_FREE_CFG寄存器选择触发CBC，OSHT，或FREE保护的信号。
  [15] reserved ro — 保留。
  [14:12] rg_oca_evtb2_inc rw — EMEVTB2有效且TCCNT计数方向递增时，APTx_PWMA的输出状态。 000：不做任何动作； 001：低电平； 010：高电平； 011：锁定电平； 100：翻转电平； 其他：高阻态。
  [11:9] rg_oca_evtb1_inc rw — EMEVTB1有效且TCCNT计数方向递增时，APTx_PWMA的输出状态。 000：不做任何动作； 001：低电平； 010：高电平； 011：锁定电平； 100：翻转电平； 其他：高阻态。
  [8:6] rg_oca_evta2_inc rw — EMEVTA2有效且TCCNT计数方向递增时，APTx_PWMA的输出状态。 000：不做任何动作； 001：低电平； 010：高电平； 011：锁定电平； 100：翻转电平； 其他：高阻态。
  [5:3] rg_oca_evta1_inc rw — EMEVTA1有效且TCCNT计数方向递增时，APTx_PWMA的输出状态。 000：不做任何动作； 001：低电平； 010：高电平； 011：锁定电平； 100：翻转电平； 其他：高阻态。
  [2:0] rg_oca_evtio_inc rw — CBC、OSHT、FREE保护生效且TCCNT计数方向递增时，APTx_PWMA的输出状态。 000：不做任何动作； 001：低电平； 010：高电平； 011：锁定电平； 100：翻转电平； 其他：高阻态。 配置OC_CBC_CFG，OC_OSHT_CFG，OC_FREE_CFG寄存器选择触发CBC，OSHT，或FREE保护的信号。
0x314 OC_ACT_B reset 0x70007 — OC_ACT_B为APTx_PWMB输出保护寄存器。支持写保护。
  [31] reserved ro — 保留。
  [30:28] rg_ocb_evtb2_dec rw — EMEVTB2有效且TCCNT计数方向递减时，APTx_PWMB的输出状态。 000：不做任何动作； 001：低电平； 010：高电平； 011：锁定电平； 100：翻转电平； 其他：高阻态。
  [27:25] rg_ocb_evtb1_dec rw — EMEVTB1有效且TCCNT计数方向递减时，APTx_PWMB的输出状态。 000：不做任何动作； 001：低电平； 010：高电平； 011：锁定电平； 100：翻转电平； 其他：高阻态。
  [24:22] rg_ocb_evta2_dec rw — EMEVTA2有效且TCCNT计数方向递减时，APTx_PWMB的输出状态。 000：不做任何动作； 001：低电平； 010：高电平； 011：锁定电平； 100：翻转电平； 其他：高阻态。
  [21:19] rg_ocb_evta1_dec rw — EMEVTA1有效且TCCNT计数方向递减时，APTx_PWMB的输出状态。 000：不做任何动作； 001：低电平； 010：高电平； 011：锁定电平； 100：翻转电平； 其他：高阻态。
  [18:16] rg_ocb_evtio_dec rw — CBC，OSHT，FREE保护生效且TCCNT计数方向递减时，APTx_PWMB的输出状态。 000：不做任何动作； 001：低电平； 010：高电平； 011：锁定电平； 100：翻转电平； 其他：高阻态。 配置OC_CBC_CFG，OC_OSHT_CFG，OC_FREE_CFG寄存器选择触发CBC，OSHT，或FREE保护的信号。
  [15] reserved ro — 保留。
  [14:12] rg_ocb_evtb2_inc rw — EMEVTB2有效且TCCNT计数方向递增时，APTx_PWMB的输出状态。 000：不做任何动作； 001：低电平； 010：高电平； 011：锁定电平； 100：翻转电平； 其他：高阻态。
  [11:9] rg_ocb_evtb1_inc rw — EMEVTB1有效且TCCNT计数方向递增时，APTx_PWMB的输出状态。 000：不做任何动作； 001：低电平； 010：高电平； 011：锁定电平； 100：翻转电平； 其他：高阻态。
  [8:6] rg_ocb_evta2_inc rw — EMEVTA2有效且TCCNT计数方向递增时，APTx_PWMB的输出状态。 000：不做任何动作； 001：低电平； 010：高电平； 011：锁定电平； 100：翻转电平； 其他：高阻态。
  [5:3] rg_ocb_evta1_inc rw — EMEVTA1有效且TCCNT计数方向递增时，APTx_PWMB的输出状态。 000：不做任何动作； 001：低电平； 010：高电平； 011：锁定电平； 100：翻转电平； 其他：高阻态。
  [2:0] rg_ocb_evtio_inc rw — CBC，OSHT，FREE保护生效且TCCNT计数方向递增时，APTx_PWMB的输出状态。 000：不做任何动作； 001：低电平； 010：高电平； 011：锁定电平； 100：翻转电平； 其他：高阻态。 配置OC_CBC_CFG，OC_OSHT_CFG，OC_FREE_CFG寄存器选择触发CBC，OSHT，或FREE保护的信号。
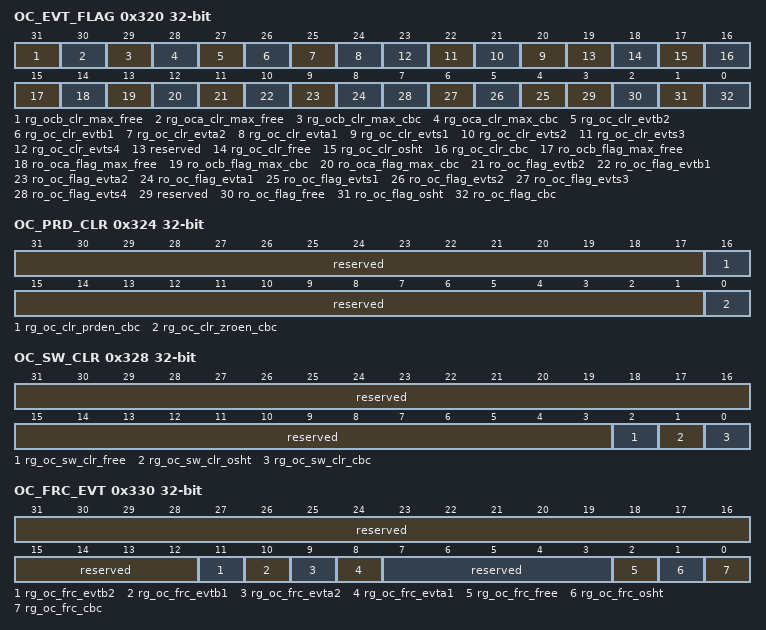
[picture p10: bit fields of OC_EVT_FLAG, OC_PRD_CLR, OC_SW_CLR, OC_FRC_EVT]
0x320 OC_EVT_FLAG — OC_EVT_FLAG为事件中断标志和清除寄存器。根据INT_EVT_EN bit[15]~bit[0]配置的中断使能，相应的OC_EVT_FLAG bit[15:0]有效会触发事件中断APTxEVTINT，相应的OC_EVT_FLAG bit[15:0]。对OC_EVT_FLAG bit[31:16]写1会清除相应的事件中断标志。支持写保护。
  [31] rg_ocb_clr_max_free rw write-1-clears — B路FREE保护超时事件中断标志位的清除位，写1清零。 0：写0无效； 1：写1有效，清除ro_oc_flag_ocb_max_free。
  [30] rg_oca_clr_max_free rw write-1-clears — A路FREE最长保护事件中断标志位的清除位，写1清零。 0：写0无效； 1：写1有效，清除ro_oc_flag_oca_max_free。
  [29] rg_ocb_clr_max_cbc rw write-1-clears — B路CBC最长保护事件中断标志位的清除位，写1清零。 0：写0无效； 1：写1有效，清除ro_oc_flag_ocb_max_cbc。
  [28] rg_oca_clr_max_cbc rw write-1-clears — A路CBC最长保护事件中断标志位的清除位，写1清零。 0：写0无效； 1：写1有效，清除ro_oc_flag_oca_max_cbc。
  [27] rg_oc_clr_evtb2 rw write-1-clears — EMEVTB2事件中断标志的清除位，写1清零。 0：写0无效； 1：写1有效。
  [26] rg_oc_clr_evtb1 rw write-1-clears — EMEVTB1事件中断标志的清除位，写1清零。 0：写0无效； 1：写1有效。
  [25] rg_oc_clr_evta2 rw write-1-clears — EMEVTA2事件中断标志的清除位，写1清零。 0：写0无效； 1：写1有效。
  [24] rg_oc_clr_evta1 rw write-1-clears — EMEVTA1事件中断标志的清除位，写1清零。 0：写0无效； 1：写1有效。
  [n+19] rg_oc_clr_evts{n} rw write-1-clears (n=1..4) — SYSEVT{n}事件中断标志的清除位，写1清零。 0：写0无效； 1：写1有效。
  [19] reserved ro — 保留。
  [18] rg_oc_clr_free rw write-1-clears — FREE事件标志位的清除位，写1请0。 0：写0无效； 1：写1有效，清除ro_oc_flag_free。
  [17] rg_oc_clr_osht rw write-1-clears — OSHT事件标志位的清除位，写1请0。 0：写0无效； 1：写1有效，清除ro_oc_flag_osht。
  [16] rg_oc_clr_cbc rw write-1-clears — CBC事件中断标志位的清除位，写1清零。 0：写0无效； 1：写1有效，清除ro_oc_flag_cbc。
  [15] ro_ocb_flag_max_free ro — B路FREE最长保护事件中断标志位。当B路FREE保护时间大于等于OC_PMAX_B时此中断有效。 0：B路FREE最长保护中断无效； 1：B路FREE最长保护中断有效。
  [14] ro_oca_flag_max_free ro — A路FREE最长保护事件中断标志位。当A路FREE保护时间大于等于OC_PMAX_A时此中断有效。 0：A路FREE最长保护中断无效； 1：A路FREE最长保护中断有效。
  [13] ro_ocb_flag_max_cbc ro — B路CBC最长保护事件中断标志位。当B路CBC保护时间大于等于OC_PMAX_B时此中断有效。 0：B路CBC最长保护中断无效； 1：B路CBC最长保护中断有效。
  [12] ro_oca_flag_max_cbc ro — A路CBC最长保护事件中断标志位。当A路CBC保护时间大于等于OC_PMAX_A时此中断有效。 0：A路CBC最长保护中断无效； 1：A路CBC最长保护中断有效。
  [11] ro_oc_flag_evtb2 ro — EMEVTB2事件中断标志位。 0：EMEVTB2故障信号无效； 1：EMEVTB2故障信号有效。
  [10] ro_oc_flag_evtb1 ro — EMEVTB1事件中断标志位。 0：EMEVTB1故障信号无效； 1：EMEVTB1故障信号有效。
  [9] ro_oc_flag_evta2 ro — EMEVTA2事件中断标志位。 0：EMEVTA2故障信号无效； 1：EMEVTA2故障信号有效。
  [8] ro_oc_flag_evta1 ro — EMEVTA1事件中断标志位。 0：EMEVTA1故障信号无效； 1：EMEVTA1故障信号有效。
  [n+3] ro_oc_flag_evts{n} ro (n=1..4) — SYSEVT{n}事件中断标志位。 0：SYSEVT{n}故障信号无效； 1：SYSEVT{n}故障信号有效。
  [3] reserved ro — 保留。
  [2] ro_oc_flag_free ro — FREE事件中断标志位。 0：FREE事件中断无效； 1：FREE事件中断有效。
  [1] ro_oc_flag_osht ro — OSHT事件中断标志位。 0：OSHT事件中断无效； 1：OSHT事件中断有效。
  [0] ro_oc_flag_cbc ro — CBC事件中断标志位。 0：CBC事件中断无效； 1：CBC事件中断有效。
0x324 OC_PRD_CLR — OC_PRD_CLR为CBC周期性保护自动清除寄存器。支持写保护。
  [31:17] reserved ro — 保留。
  [16] rg_oc_clr_prden_cbc rw — 是否在CNT_PRD有效时清除对APTx_PWMA/APTx_PWMB的CBC保护。 0：不使能； 1：使能。
  [15:1] reserved ro — 保留。
  [0] rg_oc_clr_zroen_cbc rw — 是否在CNT_ZERO有效时清除对APTx_PWMA/APTx_PWMB的CBC保护。 0：不使能； 1：使能。
0x328 OC_SW_CLR — OC_SW_CLR为清除CBC/OSHT/FREE保护寄存器。支持写保护。支持LINK。
  [31:3] reserved ro — 保留。
  [2] rg_oc_sw_clr_free rw — 清除FREE保护。 0：无效。 1：清除对APTx_PWMA/APTx_PWMB的FREE保护。写1后不会自动清零。
  [1] rg_oc_sw_clr_osht rw write-1-clears — 清除OSHT保护。 0：无效。 1：清除对APTx_PWMA/APTx_PWMB的OSHT保护。写1后自动清零。
  [0] rg_oc_sw_clr_cbc rw write-1-clears — 清除CBC保护。 0：无效。 1：清除对APTx_PWMA/APTx_PWMB的CBC保护。写1后自动清零。
0x330 OC_FRC_EVT — OC_FRC_EVT为强制产生故障信号寄存器。支持写保护。支持LINK。
  [31:12] reserved ro — 保留。
  [11] rg_oc_frc_evtb2 rw — 强制产生EMEVTB2故障信号。 0：无效； 1：有效。
  [10] rg_oc_frc_evtb1 rw — 强制产生EMEVTB1故障信号。 0：无效； 1：有效。
  [9] rg_oc_frc_evta2 rw — 强制产生EMEVTA2故障信号。 0：无效； 1：有效。
  [8] rg_oc_frc_evta1 rw — 强制产生EMEVTA1故障信号。 0：无效； 1：有效。
  [7:3] reserved ro — 保留。
  [2] rg_oc_frc_free rw — 强制产生FREE保护。 0：无效； 1：有效。
  [1] rg_oc_frc_osht rw — 强制产生OSHT保护。 0：无效； 1：有效。
  [0] rg_oc_frc_cbc rw — 强制产生CBC保护。 0：无效； 1：有效。
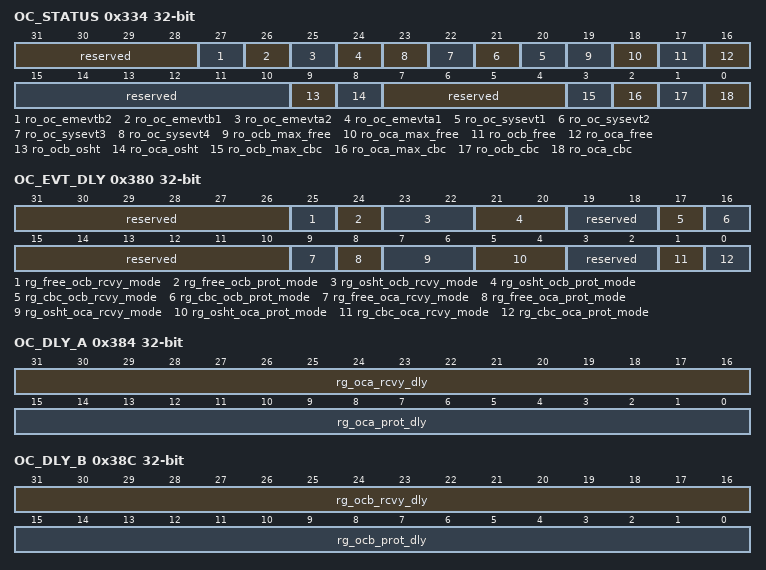
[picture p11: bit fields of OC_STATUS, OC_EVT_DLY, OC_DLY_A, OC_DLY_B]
0x334 OC_STATUS ro — OC_STATUS为事件中断源实时状态寄存器。事件中断源触发OC_EVT_FLAG事件中断标志寄存器置位。
  [31:28] reserved — 保留。
  [27] ro_oc_emevtb2 — EMEVTB2实时状态。
  [26] ro_oc_emevtb1 — EMEVTB1实时状态。
  [25] ro_oc_emevta2 — EMEVTA2实时状态。
  [24] ro_oc_emevta1 — EMEVTA1实时状态。
  [n+19] ro_oc_sysevt{n} (n=1..4) — SYSEVT{n}实时状态。
  [19] ro_ocb_max_free — B路FREE保护超时实时状态。 0：保护未超时； 1：保护已超时。
  [18] ro_oca_max_free — A路FREE保护超时实时状态。 0：保护未超时； 1：保护已超时。
  [17] ro_ocb_free — B路FREE保护实时状态。 0：FREE保护未生效； 1：FREE保护正在生效。
  [16] ro_oca_free — A路FREE保护实时状态。 0：FREE保护未生效； 1：FREE保护正在生效。
  [15:10] reserved — 保留。
  [9] ro_ocb_osht — B路OSHT保护实时状态。 0：保护未生效； 1：保护正在生效。
  [8] ro_oca_osht — A路OSHT保护实时状态。 0：保护未生效； 1：保护正在生效。
  [7:4] reserved — 保留。
  [3] ro_ocb_max_cbc — B路CBC保护超时实时状态。 0：保护未超时； 1：保护已超时。
  [2] ro_oca_max_cbc — A路CBC保护超时实时状态。 0：保护未超时； 1：保护已超时。
  [1] ro_ocb_cbc — B路CBC保护实时状态。 0：保护未生效； 1：保护正在生效。
  [0] ro_oca_cbc — A路CBC保护实时状态。 0：保护未生效； 1：保护正在生效。
0x380 OC_EVT_DLY — OC_EVT_DLY为延时保护配置寄存器。支持写保护。
  [31:26] reserved ro — 保留。
  [25] rg_free_ocb_rcvy_mode rw — B路FREE延时恢复模式配置。 0：不延时； 1：延迟恢复，延迟OC_DLY_B个APTxCLK周期。
  [24] rg_free_ocb_prot_mode rw — B路FREE延时保护模式配置。 0：不延时； 1：延迟保护，延迟OC_DLY_B个APTxCLK周期。
  [23:22] rg_osht_ocb_rcvy_mode rw — B路OSHT延时恢复模式配置。 00：不延时； 01：延迟恢复，延迟OC_DLY_B个APTxCLK周期； 10：对齐恢复，仅对OSHT保护的故障信号有效，软件写OC_SW_CLR清除OSHT保护后，延迟到CNT_ZERO有效时恢复； 11：对齐恢复，仅对OSHT保护的故障信号有效，软件写OC_SW_CLR清除OSHT保护后，延迟到CNT_PRD有效时恢复。
  [21:20] rg_osht_ocb_prot_mode rw — B路OSHT延时保护模式配置。 00：不延时； 01：延迟保护，延迟OC_DLY_B个APTxCLK周期。 10：对齐保护，当OC_EVT_FLAG故障标志有效之后，延迟到CNT_ZERO有效时保护； 11：对齐保护，当OC_EVT_FLAG故障标志有效之后，延迟到CNT_PRD有效时保护。
  [19:18] reserved ro — 保留。
  [17] rg_cbc_ocb_rcvy_mode rw — B路CBC延时恢复模式配置。 0：不延时； 1：延迟恢复，延迟OC_DLY_B个APTxCLK周期。
  [16] rg_cbc_ocb_prot_mode rw — B路CBC延时保护模式配置。 0：不延时； 1：延迟保护，延迟OC_DLY_B个APTxCLK周期。
  [15:10] reserved ro — 保留。
  [9] rg_free_oca_rcvy_mode rw — A路FREE延时恢复模式配置。 0：不延时； 1：延迟恢复，延迟OC_DLY_A个APTxCLK周期。
  [8] rg_free_oca_prot_mode rw — A路FREE延时保护模式配置。 0：不延时； 1：延迟保护，延迟OC_DLY_A个APTxCLK周期。
  [7:6] rg_osht_oca_rcvy_mode rw — A路OSHT延时恢复模式配置。 00：不延时； 01：延迟恢复，延迟OC_DLY_A个APTxCLK周期； 10：对齐恢复，软件写OC_EVT_FLAG清除故障标志之后，延迟到CNT_ZERO有效时恢复； 11：对齐恢复，软件写OC_EVT_FLAG清除故障标志之后，延迟到CNT_PRD有效时恢复。
  [5:4] rg_osht_oca_prot_mode rw — A路OSHT延时保护模式配置。 00：不延时； 01：延迟保护，延迟OC_DLY_A个APTxCLK周期； 10：对齐保护，当OC_EVT_FLAG故障标志有效之后，延迟到CNT_ZERO有效时保护； 11：对齐保护，当OC_EVT_FLAG故障标志有效之后，延迟到CNT_PRD有效时保护。
  [3:2] reserved ro — 保留。
  [1] rg_cbc_oca_rcvy_mode rw — A路CBC延时恢复模式配置。 0：不延时； 1：延迟恢复，延迟OC_DLY_A个APTxCLK周期。
  [0] rg_cbc_oca_prot_mode rw — A路CBC延时保护模式配置。 0：不延时； 1：延迟保护，延迟OC_DLY_A个APTxCLK周期。
0x384 OC_DLY_A rw — OC_DLY_A为APTx_PWMA延时保护和延时恢复配置寄存器。支持写保护。
  [31:16] rg_oca_rcvy_dly — A路延时恢复时间配置。减1配置。
  [15:0] rg_oca_prot_dly — A路延时保护时间配置。减1配置。
0x38C OC_DLY_B rw — OC_DLY_B为APTx_PWMB延时保护和延时恢复配置寄存器。支持写保护。
  [31:16] rg_ocb_rcvy_dly — B路延时恢复时间配置。减1配置。
  [15:0] rg_ocb_prot_dly — B路延时保护时间配置。减1配置。
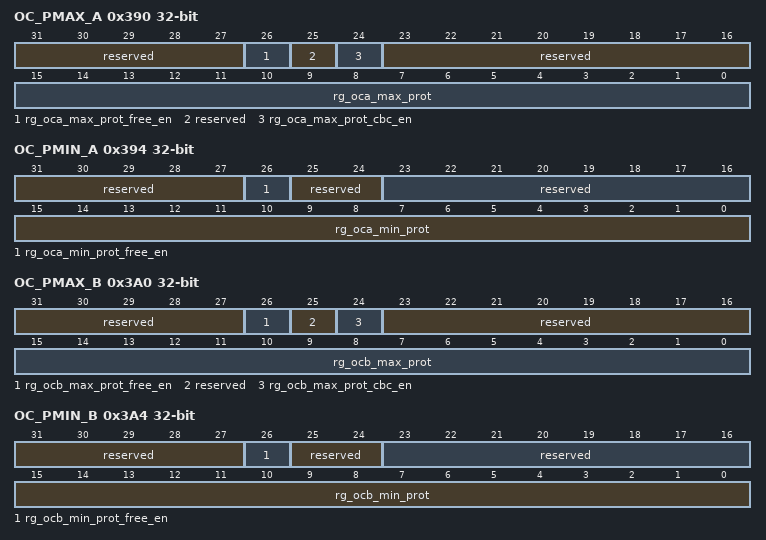
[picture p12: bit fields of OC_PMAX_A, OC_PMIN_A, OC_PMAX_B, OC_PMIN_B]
0x390 OC_PMAX_A — OC_PMAX_A为APTx_PWMA保护最长时间配置寄存器。支持写保护。
  [31:27] reserved ro — 保留。
  [26] rg_oca_max_prot_free_en rw — 是否使能A路FREE最长保护时间限制。 0：不使能A路FREE最长保护时间限制； 1：使能A路FREE最长保护时间限制。 注意：软件先配置rg_oca_max_prot，再配置rg_oca_max_prot_free_en使能FREE最长保护时间限制。
  [25] reserved ro — 保留。
  [24] rg_oca_max_prot_cbc_en rw — 是否使能A路CBC最长保护时间限制。 0：不使能A路CBC最长保护时间限制； 1：使能A路CBC最长保护时间限制。 注意：软件先配置rg_oca_max_prot，再配置rg_oca_max_prot_cbc_en使能CBC最长保护时间限制。
  [23:16] reserved ro — 保留。
  [15:0] rg_oca_max_prot rw — A路最长保护时间限制，当保护时间超过最长保护时间，自动将保护故障标志清除。 对OSHT保护不生效，仅对自由保护和CBC保护的故障信号生效。 0x0：最长保护时间为1个APTxCLK周期； 0x1：最长保护时间为2个APTxCLK周期； 0x2：最长保护时间为3个APTxCLK周期； … 0xFFFF：最长保护时间为65536个APTxCLK周期。
0x394 OC_PMIN_A — OC_PMIN_A为APTx_PWMA保护最短时间配置寄存器。支持写保护。
  [31:27] reserved ro — 保留。
  [26] rg_oca_min_prot_free_en rw — 是否使能A路FREE最短保护时间限制。 0：不使能A路FREE最短保护时间限制； 1：使能A路FREE最短保护时间限制。
  [25:24] reserved ro — 保留。
  [23:16] reserved ro — 保留。
  [15:0] rg_oca_min_prot rw — A路最短保护时间限制，当保护时间小于最短保护时间，维持保护直到等于最短保护时间。 对OSHT保护和CBC保护不生效，仅对自由保护的故障信号生效。 0x0：保护时间最短不低于1个APTxCLK周期； 0x1：保护时间最短不低于2个APTxCLK周期； 0x2：保护时间最短不低于3个APTxCLK周期； … 0xFFFF：保护时间最短不低于65536个APTxCLK周期。
0x3A0 OC_PMAX_B — OC_PMAX_B为APTx_PWMB保护最长时间配置寄存器。支持写保护。
  [31:27] reserved ro — 保留。
  [26] rg_ocb_max_prot_free_en rw — 是否使能B路FREE最长保护时间限制。 0：不使能B路FREE最长保护时间限制； 1：使能B路FREE最长保护时间限制。 注意：软件先配置rg_ocb_max_prot，再配置rg_ocb_max_prot_free_en使能FREE最长保护时间限制。
  [25] reserved ro — 保留。
  [24] rg_ocb_max_prot_cbc_en rw — 是否使能B路CBC最长保护时间限制。 0：不使能B路CBC最长保护时间限制； 1：使能B路CBC最长保护时间限制。 注意：软件先配置rg_ocb_max_prot，再配置rg_ocb_max_prot_cbc_en使能CBC最长保护时间限制。
  [23:16] reserved ro — 保留。
  [15:0] rg_ocb_max_prot rw — B路保护最长时间限制，当保护时间超过最长保护时间，自动将保护故障标志清除。 对OSHT保护不生效，仅对自由保护和CBC保护的故障信号生效。 0x0：最长保护时间为1个APTxCLK周期； 0x1：最长保护时间为2个APTxCLK周期； 0x2：最长保护时间为3个APTxCLK周期； … 0xFFFF：最长保护时间为65536个APTxCLK周期。
0x3A4 OC_PMIN_B — OC_PMIN_B为APTx_PWMB保护最短时间配置寄存器。支持写保护。
  [31:27] reserved ro — 保留。
  [26] rg_ocb_min_prot_free_en rw — 是否使能B路FREE最短保护时间限制。 0：不使能B路FREE最短保护时间限制； 1：使能B路FREE最短保护时间限制。
  [25:24] reserved ro — 保留。
  [23:16] reserved ro — 保留。
  [15:0] rg_ocb_min_prot rw — B路保护最短时间限制，当保护时间小于最短保护时间，维持保护直到等于最短保护时间。 对OSHT保护和CBC保护不生效，仅对自由保护的故障信号生效。 0x0：保护时间最短不低于1个APTxCLK周期； 0x1：保护时间最短不低于2个APTxCLK周期； 0x2：保护时间最短不低于3个APTxCLK周期； … 0xFFFF：保护时间最短不低于65536个APTxCLK周期。
